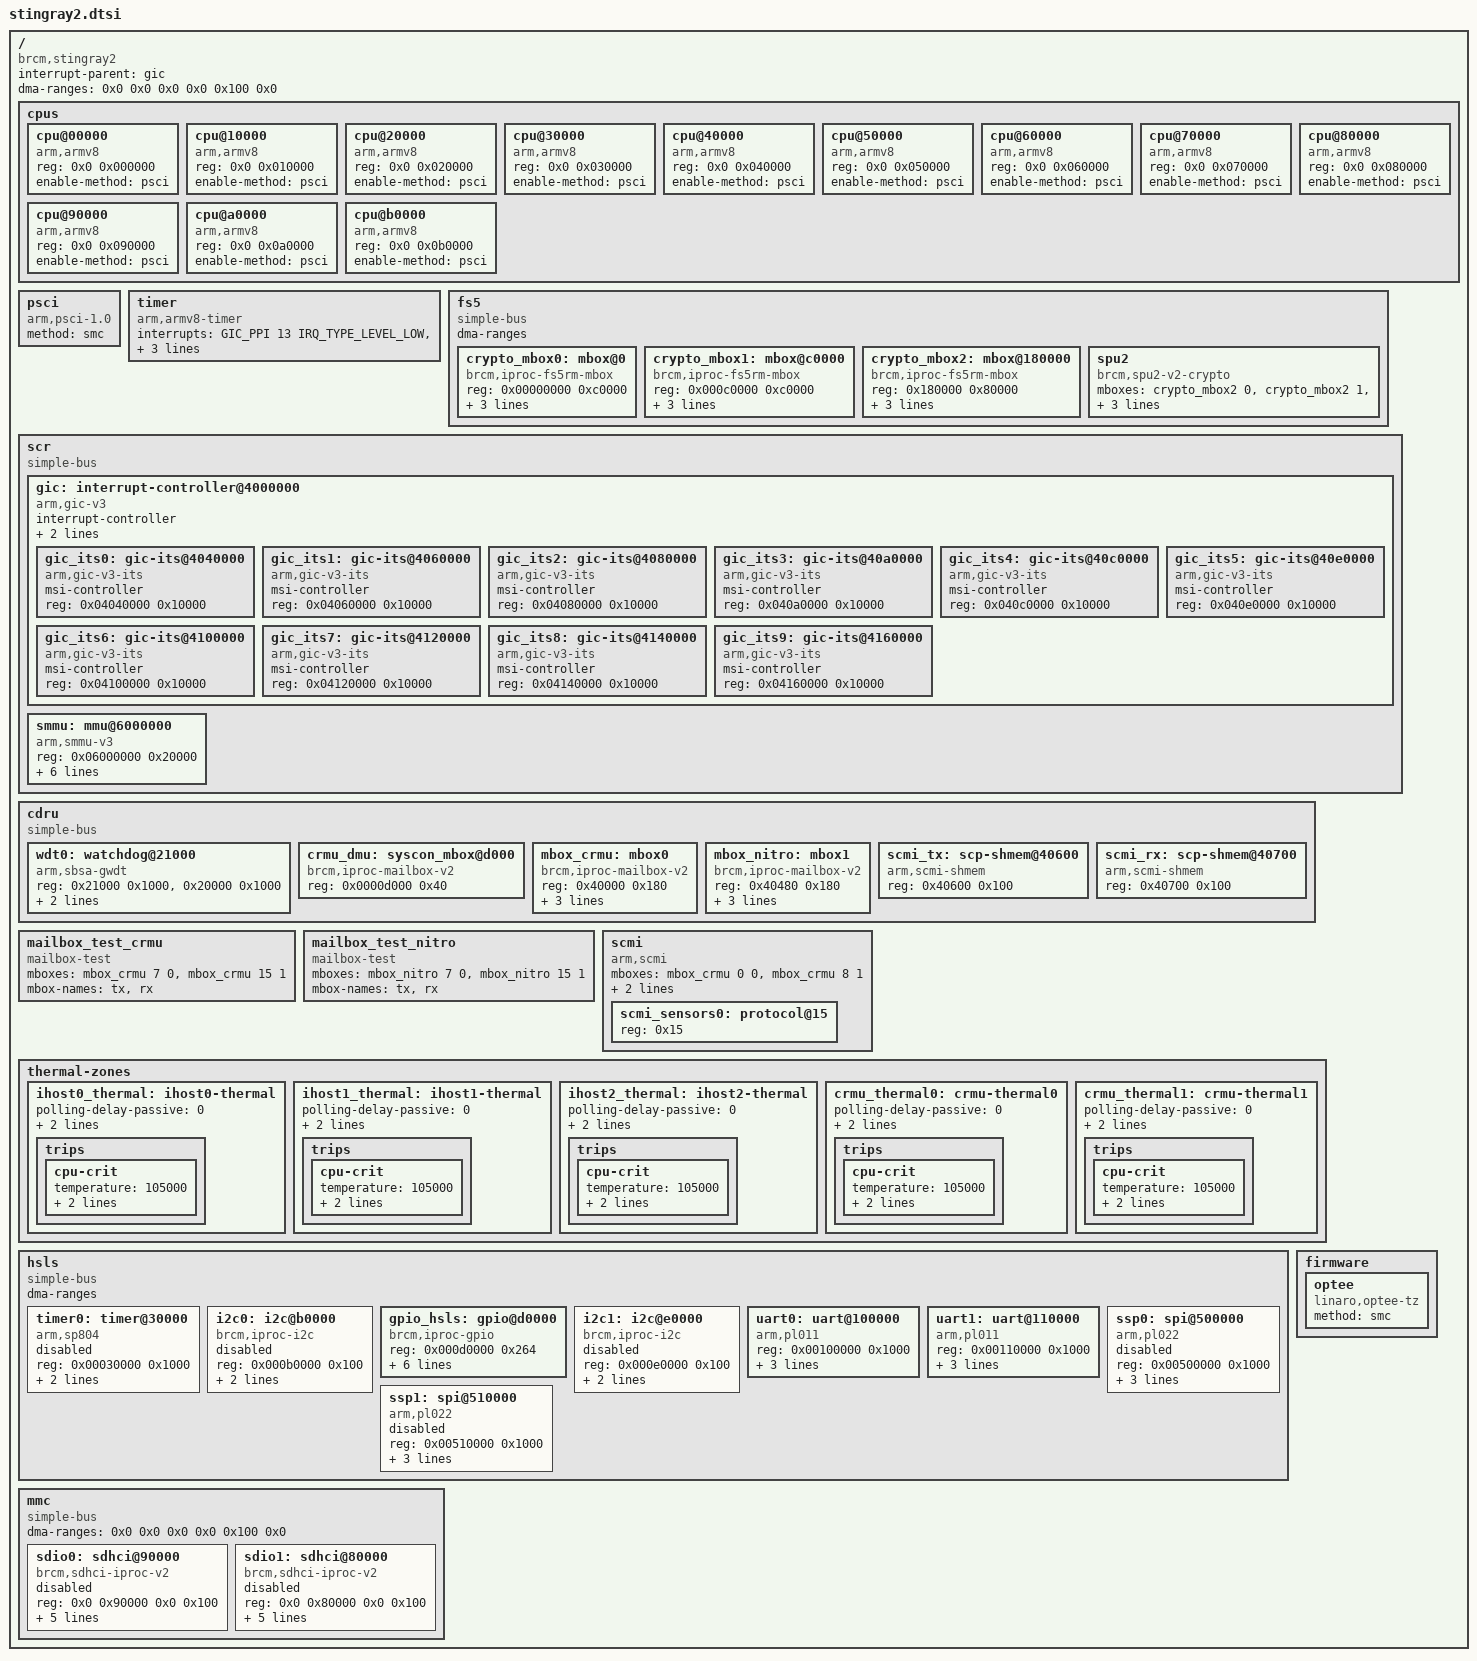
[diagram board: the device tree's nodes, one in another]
// SPDX-License-Identifier: (GPL-2.0 or BSD-3-Clause)
/*
 *  Copyright(c) 2020 Broadcom
 */

#include <dt-bindings/interrupt-controller/arm-gic.h>

/ {
	compatible = "brcm,stingray2";
	interrupt-parent = <&gic>;
	#address-cells = <2>;
	#size-cells = <2>;
	dma-ranges = <0x0 0x0 0x0 0x0 0x100 0x0>;

	cpus {
		#address-cells = <2>;
		#size-cells = <0>;

		cpu@00000 {
			device_type = "cpu";
			compatible = "arm,armv8";
			reg = <0x0 0x000000>;
			enable-method = "psci";
		};

		cpu@10000 {
			device_type = "cpu";
			compatible = "arm,armv8";
			reg = <0x0 0x010000>;
			enable-method = "psci";
		};

		cpu@20000 {
			device_type = "cpu";
			compatible = "arm,armv8";
			reg = <0x0 0x020000>;
			enable-method = "psci";
		};

		cpu@30000 {
			device_type = "cpu";
			compatible = "arm,armv8";
			reg = <0x0 0x030000>;
			enable-method = "psci";
		};

		cpu@40000 {
			device_type = "cpu";
			compatible = "arm,armv8";
			reg = <0x0 0x040000>;
			enable-method = "psci";
		};

		cpu@50000 {
			device_type = "cpu";
			compatible = "arm,armv8";
			reg = <0x0 0x050000>;
			enable-method = "psci";
		};

		cpu@60000 {
			device_type = "cpu";
			compatible = "arm,armv8";
			reg = <0x0 0x060000>;
			enable-method = "psci";
		};

		cpu@70000 {
			device_type = "cpu";
			compatible = "arm,armv8";
			reg = <0x0 0x070000>;
			enable-method = "psci";
		};

		cpu@80000 {
			device_type = "cpu";
			compatible = "arm,armv8";
			reg = <0x0 0x080000>;
			enable-method = "psci";
		};

		cpu@90000 {
			device_type = "cpu";
			compatible = "arm,armv8";
			reg = <0x0 0x090000>;
			enable-method = "psci";
		};

		cpu@a0000 {
			device_type = "cpu";
			compatible = "arm,armv8";
			reg = <0x0 0x0a0000>;
			enable-method = "psci";
		};

		cpu@b0000 {
			device_type = "cpu";
			compatible = "arm,armv8";
			reg = <0x0 0x0b0000>;
			enable-method = "psci";
		};
	};

	psci {
		compatible = "arm,psci-1.0";
		method = "smc";
	};

	timer {
		compatible = "arm,armv8-timer";
		interrupts = <GIC_PPI 13 IRQ_TYPE_LEVEL_LOW>,
			     <GIC_PPI 14 IRQ_TYPE_LEVEL_LOW>,
			     <GIC_PPI 11 IRQ_TYPE_LEVEL_LOW>,
			     <GIC_PPI 10 IRQ_TYPE_LEVEL_LOW>;
	};

	fs5: fs5 {
		compatible = "simple-bus";
		dma-ranges;
		#address-cells = <1>;
		#size-cells = <1>;
		ranges = <0x0 0x0 0x47000000 0x00900000>;

		crypto_mbox0: mbox@0 {
			compatible = "brcm,iproc-fs5rm-mbox";
			/* 12 channels for mbox0 */
			reg = <0x00000000 0xc0000>;
			#mbox-cells = <1>;
			msi-parent = <&gic_its8 0xf0020>;
			iommus = <&smmu 0xf0000>,
				 <&smmu 0xf0020>;
			dma-coherent;
		};

		crypto_mbox1: mbox@c0000 {
			compatible = "brcm,iproc-fs5rm-mbox";
			/* 12 channels for mbox1 */
			reg = <0x000c0000 0xc0000>;
			#mbox-cells = <1>;
			msi-parent = <&gic_its8 0xf0021>;
			iommus = <&smmu 0xf0001>,
				 <&smmu 0xf0021>;
			dma-coherent;
		};

		crypto_mbox2: mbox@180000 {
			compatible = "brcm,iproc-fs5rm-mbox";
			/* 8 channels for mbox2 */
			reg = <0x180000 0x80000>;
			#mbox-cells = <1>;
			msi-parent = <&gic_its8 0xf0022>;
			iommus = <&smmu 0xf0002>,
				 <&smmu 0xf0022>;
			dma-coherent;
		};

		spu2: spu2 {
			compatible = "brcm,spu2-v2-crypto";
			/*
			 * Allocating 8 channels from crypto mbox2 for kernel
			 * spu2 driver.
			 */
			mboxes = <&crypto_mbox2 0>,
				 <&crypto_mbox2 1>,
				 <&crypto_mbox2 2>,
				 <&crypto_mbox2 3>,
				 <&crypto_mbox2 4>,
				 <&crypto_mbox2 5>,
				 <&crypto_mbox2 6>,
				 <&crypto_mbox2 7>;
		};
	};

	scr {
		compatible = "simple-bus";
		#address-cells = <1>;
		#size-cells = <1>;
		ranges = <0x0 0x0 0x50000000 0x07000000>;

		gic: interrupt-controller@4000000 {
			compatible = "arm,gic-v3";
			#interrupt-cells = <3>;
			#address-cells = <1>;
			#size-cells = <1>;
			ranges;
			interrupt-controller;
			reg = <0x4000000 0x010000>, /* GICD */
			      <0x4180000 0x1800000>; /* GICR */
			interrupts = <GIC_PPI 9 IRQ_TYPE_LEVEL_HIGH>;

			gic_its0: gic-its@4040000 {
				compatible = "arm,gic-v3-its";
				msi-controller;
				#msi-cells = <1>;
				reg = <0x04040000 0x10000>;
			};

			gic_its1: gic-its@4060000 {
				compatible = "arm,gic-v3-its";
				msi-controller;
				#msi-cells = <1>;
				reg = <0x04060000 0x10000>;
			};

			gic_its2: gic-its@4080000 {
				compatible = "arm,gic-v3-its";
				msi-controller;
				#msi-cells = <1>;
				reg = <0x04080000 0x10000>;
			};

			gic_its3: gic-its@40a0000 {
				compatible = "arm,gic-v3-its";
				msi-controller;
				#msi-cells = <1>;
				reg = <0x040a0000 0x10000>;
			};

			gic_its4: gic-its@40c0000 {
				compatible = "arm,gic-v3-its";
				msi-controller;
				#msi-cells = <1>;
				reg = <0x040c0000 0x10000>;
			};

			gic_its5: gic-its@40e0000 {
				compatible = "arm,gic-v3-its";
				msi-controller;
				#msi-cells = <1>;
				reg = <0x040e0000 0x10000>;
			};

			gic_its6: gic-its@4100000 {
				compatible = "arm,gic-v3-its";
				msi-controller;
				#msi-cells = <1>;
				reg = <0x04100000 0x10000>;
			};

			gic_its7: gic-its@4120000 {
				compatible = "arm,gic-v3-its";
				msi-controller;
				#msi-cells = <1>;
				reg = <0x04120000 0x10000>;
			};

			gic_its8: gic-its@4140000 {
				compatible = "arm,gic-v3-its";
				msi-controller;
				#msi-cells = <1>;
				reg = <0x04140000 0x10000>;
			};

			gic_its9: gic-its@4160000 {
				compatible = "arm,gic-v3-its";
				msi-controller;
				#msi-cells = <1>;
				reg = <0x04160000 0x10000>;
			};
		};

		smmu: mmu@6000000 {
			compatible = "arm,smmu-v3";
			reg = <0x06000000 0x20000>;
			#global-interrupts = <1>;
			interrupts = <GIC_SPI 34 IRQ_TYPE_EDGE_RISING>,
				     <GIC_SPI 37 IRQ_TYPE_EDGE_RISING>,
				     <GIC_SPI 32 IRQ_TYPE_EDGE_RISING>,
				     <GIC_SPI 29 IRQ_TYPE_EDGE_RISING>;
			interrupt-names = "eventq", "priq", "cmdq-sync", "gerror";
			dma-coherent;
			#iommu-cells = <1>;
		};
	};

	cdru {
		compatible = "simple-bus";
		#address-cells = <1>;
		#size-cells = <1>;
		ranges = <0x0 0x0 0x60000000 0x80000>;

		wdt0: watchdog@21000 {
			compatible = "arm,sbsa-gwdt";
			reg = <0x21000  0x1000>,
			      <0x20000  0x1000>;
			interrupts = <GIC_SPI 393 IRQ_TYPE_LEVEL_HIGH>;
			timeout-sec = <60>;
		};

		crmu_dmu: syscon_mbox@d000 {
			compatible = "brcm,iproc-mailbox-v2", "syscon";
			reg = <0x0000d000 0x40>;
		};

		mbox_crmu: mbox0 {
			compatible = "brcm,iproc-mailbox-v2";
			reg = <0x40000 0x180>;
			interrupts = <GIC_SPI 389 IRQ_TYPE_LEVEL_HIGH>;
			brcm,iproc-mbox = <&crmu_dmu 0x20 0x00>;
			brcm,iproc-mbox-ch-count = <16>;
			#mbox-cells = <2>;
		};

		mbox_nitro: mbox1 {
			compatible = "brcm,iproc-mailbox-v2";
			reg = <0x40480 0x180>;
			interrupts = <GIC_SPI 389 IRQ_TYPE_LEVEL_HIGH>;
			brcm,iproc-mbox = <&crmu_dmu 0x20 0x30>;
			brcm,iproc-mbox-ch-count = <16>;
			#mbox-cells = <2>;
		};

		scmi_tx: scp-shmem@40600 {
			compatible = "arm,scmi-shmem";
			reg = <0x40600 0x100>;
		};

		scmi_rx: scp-shmem@40700 {
			compatible = "arm,scmi-shmem";
			reg = <0x40700 0x100>;
		};
	};

	mailbox_test_crmu {
		compatible = "mailbox-test";
		mboxes = <&mbox_crmu 7 0>, <&mbox_crmu 15 1>;
		mbox-names = "tx", "rx";
	};

	mailbox_test_nitro {
		compatible = "mailbox-test";
		mboxes = <&mbox_nitro 7 0>, <&mbox_nitro 15 1>;
		mbox-names = "tx", "rx";
	};

	scmi {
		compatible = "arm,scmi";
		mboxes = <&mbox_crmu 0 0 &mbox_crmu 8 1>;
		mbox-names = "tx", "rx";
		shmem = <&scmi_tx &scmi_rx>;
		#address-cells = <1>;
		#size-cells = <0>;

		scmi_sensors0: protocol@15 {
			reg = <0x15>;
			#thermal-sensor-cells = <1>;
		};
	};

	thermal-zones {
		ihost0_thermal: ihost0-thermal {
			polling-delay-passive = <0>;
			polling-delay = <1000>;
			thermal-sensors = <&scmi_sensors0 0>;
			trips {
				cpu-crit {
					temperature = <105000>;
					hysteresis = <0>;
					type = "critical";
				};
			};
		};

		ihost1_thermal: ihost1-thermal {
			polling-delay-passive = <0>;
			polling-delay = <1000>;
			thermal-sensors = <&scmi_sensors0 1>;
			trips {
				cpu-crit {
					temperature = <105000>;
					hysteresis = <0>;
					type = "critical";
				};
			};
		};

		ihost2_thermal: ihost2-thermal {
			polling-delay-passive = <0>;
			polling-delay = <1000>;
			thermal-sensors = <&scmi_sensors0 2>;
			trips {
				cpu-crit {
					temperature = <105000>;
					hysteresis = <0>;
					type = "critical";
				};
			};
		};

		crmu_thermal0: crmu-thermal0 {
			polling-delay-passive = <0>;
			polling-delay = <1000>;
			thermal-sensors = <&scmi_sensors0 3>;
			trips {
				cpu-crit {
					temperature = <105000>;
					hysteresis = <0>;
					type = "critical";
				};
			};
		};

		crmu_thermal1: crmu-thermal1 {
			polling-delay-passive = <0>;
			polling-delay = <1000>;
			thermal-sensors = <&scmi_sensors0 4>;
			trips {
				cpu-crit {
					temperature = <105000>;
					hysteresis = <0>;
					type = "critical";
				};
			};
		};
	};

	#include "stingray2-clock.dtsi"
	#include "stingray2-idm.dtsi"

	hsls {
		compatible = "simple-bus";
		dma-ranges;
		#address-cells = <1>;
		#size-cells = <1>;
		ranges = <0x0 0x0 0x68900000 0x17700000>;

		timer0: timer@30000 {
			compatible = "arm,sp804", "arm,primecell";
			reg = <0x00030000 0x1000>;
			interrupts = <GIC_SPI 176 IRQ_TYPE_LEVEL_HIGH>;
			clocks = <&timer0_clk>;
			clock-names = "apb_pclk";
			status = "disabled";
		};

		#include "stingray2-pinctrl.dtsi"

		i2c0: i2c@b0000 {
			compatible = "brcm,iproc-i2c";
			reg = <0x000b0000 0x100>;
			#address-cells = <1>;
			#size-cells = <0>;
			interrupts = <GIC_SPI 174 IRQ_TYPE_LEVEL_HIGH>;
			clock-frequency = <100000>;
			status = "disabled";
		};

		gpio_hsls: gpio@d0000 {
			compatible = "brcm,iproc-gpio";
			reg = <0x000d0000 0x264>;
			ngpios = <60>;
			#gpio-cells = <2>;
			gpio-controller;
			gpio-ranges = <&pinmux 0 0 38>,
				      <&pinmux 38 46 2>,
				      <&pinmux 40 44 2>,
				      <&pinmux 42 38 4>,
				      <&pinmux 46 60 4>,
				      <&pinmux 50 42 2>,
				      <&pinmux 52 52 8>;
		};

		i2c1: i2c@e0000 {
			compatible = "brcm,iproc-i2c";
			reg = <0x000e0000 0x100>;
			#address-cells = <1>;
			#size-cells = <0>;
			interrupts = <GIC_SPI 175 IRQ_TYPE_LEVEL_HIGH>;
			clock-frequency = <100000>;
			status = "disabled";
		};

		uart0: uart@100000 {
			device_type = "serial";
			compatible = "arm,pl011", "arm,primecell";
			reg = <0x00100000 0x1000>;
			clocks = <&pl011_clk>, <&apb_clk>;
			clock-names = "pl0110_clk", "apb_pclk";
			interrupt-parent = <&gic>;
			interrupts = <GIC_SPI 170 IRQ_TYPE_LEVEL_HIGH>;
		};

		uart1: uart@110000 {
			device_type = "serial";
			compatible = "arm,pl011", "arm,primecell";
			reg = <0x00110000 0x1000>;
			clocks = <&pl011_clk>, <&apb_clk>;
			clock-names = "pl011_clk", "apb_pclk";
			interrupt-parent = <&gic>;
			interrupts = <GIC_SPI 171 IRQ_TYPE_LEVEL_HIGH>;
		};

		ssp0: spi@500000 {
			compatible = "arm,pl022", "arm,primecell";
			reg = <0x00500000 0x1000>;
			interrupts = <GIC_SPI 181 IRQ_TYPE_LEVEL_HIGH>;
			clocks = <&spi0_clk>, <&spi0_clk>;
			clock-names = "spiclk", "apb_pclk";
			num-cs = <1>;
			#address-cells = <1>;
			#size-cells = <0>;
			status = "disabled";
		};

		ssp1: spi@510000 {
			compatible = "arm,pl022", "arm,primecell";
			reg = <0x00510000 0x1000>;
			interrupts = <GIC_SPI 182 IRQ_TYPE_LEVEL_HIGH>;
			clocks = <&spi0_clk>, <&spi0_clk>;
			clock-names = "spiclk", "apb_pclk";
			num-cs = <1>;
			#address-cells = <1>;
			#size-cells = <0>;
			status = "disabled";
		};

	};

	mmc {
		compatible = "simple-bus";
		#address-cells = <2>;
		#size-cells = <2>;
		ranges = <0x0 0x0 0x0 0x63200000 0x0 0x100000>;
		dma-ranges = <0x0 0x0 0x0 0x0 0x100 0x0>;

		sdio0: sdhci@90000 {
			compatible = "brcm,sdhci-iproc-v2";
			reg = <0x0 0x90000 0x0 0x100>;
			interrupts = <GIC_SPI 227 IRQ_TYPE_LEVEL_HIGH>;
			bus-width = <8>;
			clocks = <&sdio0_clk>;
			iommus = <&smmu 0xf8001>;
			status = "disabled";
			dma-coherent;
		};

		sdio1: sdhci@80000 {
			compatible = "brcm,sdhci-iproc-v2";
			reg = <0x0 0x80000 0x0 0x100>;
			interrupts = <GIC_SPI 228 IRQ_TYPE_LEVEL_HIGH>;
			bus-width = <8>;
			clocks = <&sdio1_clk>;
			iommus = <&smmu 0xf8002>;
			status = "disabled";
			dma-coherent;
		};
	};

	#include "stingray2-pcie.dtsi"

	firmware {
		optee {
			compatible = "linaro,optee-tz";
			method = "smc";
		};
	};
};
